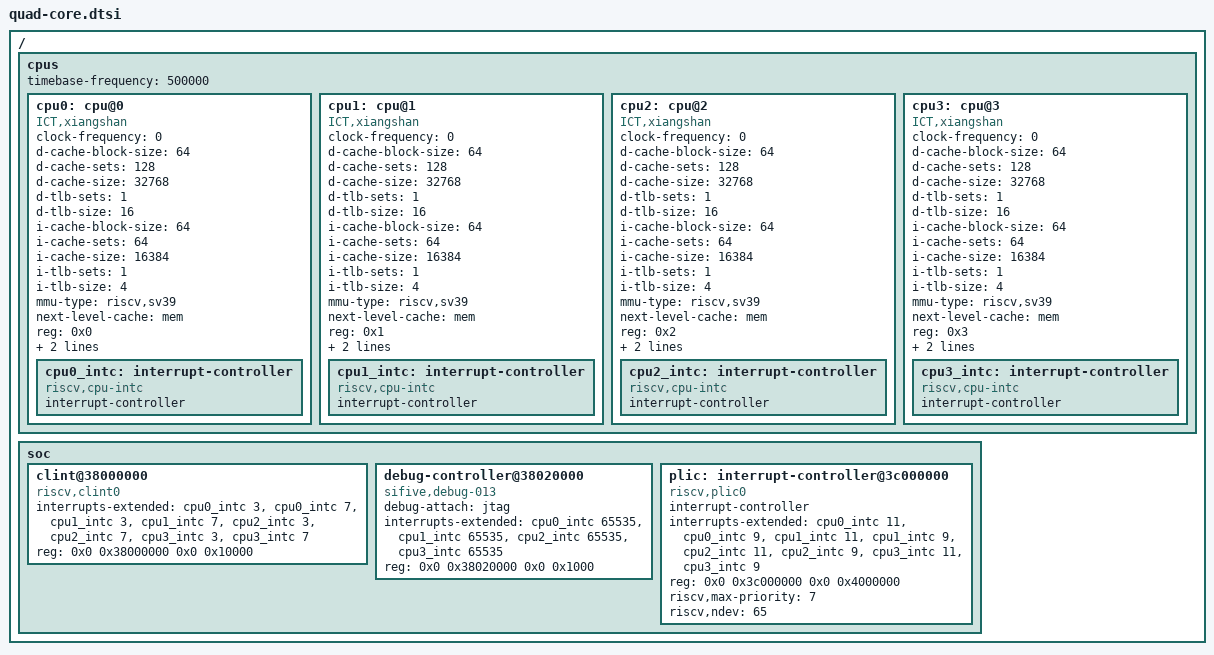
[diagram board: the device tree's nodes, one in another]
/ {
	cpus {
		#address-cells = <1>;
		#size-cells = <0>;
		timebase-frequency = <500000>;// clk freq / 100
		cpu0: cpu@0 {
			clock-frequency = <0>;
			compatible = "ICT,xiangshan", "riscv";
			d-cache-block-size = <64>;
			d-cache-sets = <128>;
			d-cache-size = <32768>;
			d-tlb-sets = <1>;
			d-tlb-size = <16>;
			device_type = "cpu";
			i-cache-block-size = <64>;
			i-cache-sets = <64>;
			i-cache-size = <16384>;
			i-tlb-sets = <1>;
			i-tlb-size = <4>;
			mmu-type = "riscv,sv39";
			next-level-cache = <&mem>;
			reg = <0x0>;
			riscv,isa = "rv64imafdc";
			status = "okay";
			tlb-split;
			cpu0_intc: interrupt-controller {
				#address-cells = <0>;
				#interrupt-cells = <1>;
				compatible = "riscv,cpu-intc";
				interrupt-controller;
			};
		};
		cpu1: cpu@1 {
			clock-frequency = <0>;
			compatible = "ICT,xiangshan", "riscv";
			d-cache-block-size = <64>;
			d-cache-sets = <128>;
			d-cache-size = <32768>;
			d-tlb-sets = <1>;
			d-tlb-size = <16>;
			device_type = "cpu";
			i-cache-block-size = <64>;
			i-cache-sets = <64>;
			i-cache-size = <16384>;
			i-tlb-sets = <1>;
			i-tlb-size = <4>;
			mmu-type = "riscv,sv39";
			next-level-cache = <&mem>;
			reg = <0x1>;
			riscv,isa = "rv64imafdc";
			status = "okay";
			tlb-split;
			cpu1_intc: interrupt-controller {
				#address-cells = <0>;
				#interrupt-cells = <1>;
				compatible = "riscv,cpu-intc";
				interrupt-controller;
			};
		};
		cpu2: cpu@2 {
			clock-frequency = <0>;
			compatible = "ICT,xiangshan", "riscv";
			d-cache-block-size = <64>;
			d-cache-sets = <128>;
			d-cache-size = <32768>;
			d-tlb-sets = <1>;
			d-tlb-size = <16>;
			device_type = "cpu";
			i-cache-block-size = <64>;
			i-cache-sets = <64>;
			i-cache-size = <16384>;
			i-tlb-sets = <1>;
			i-tlb-size = <4>;
			mmu-type = "riscv,sv39";
			next-level-cache = <&mem>;
			reg = <0x2>;
			riscv,isa = "rv64imafdc";
			status = "okay";
			tlb-split;
			cpu2_intc: interrupt-controller {
				#address-cells = <0>;
				#interrupt-cells = <1>;
				compatible = "riscv,cpu-intc";
				interrupt-controller;
			};
		};
		cpu3: cpu@3 {
			clock-frequency = <0>;
			compatible = "ICT,xiangshan", "riscv";
			d-cache-block-size = <64>;
			d-cache-sets = <128>;
			d-cache-size = <32768>;
			d-tlb-sets = <1>;
			d-tlb-size = <16>;
			device_type = "cpu";
			i-cache-block-size = <64>;
			i-cache-sets = <64>;
			i-cache-size = <16384>;
			i-tlb-sets = <1>;
			i-tlb-size = <4>;
			mmu-type = "riscv,sv39";
			next-level-cache = <&mem>;
			reg = <0x3>;
			riscv,isa = "rv64imafdc";
			status = "okay";
			tlb-split;
			cpu3_intc: interrupt-controller {
				#address-cells = <0>;
				#interrupt-cells = <1>;
				compatible = "riscv,cpu-intc";
				interrupt-controller;
			};
		};
	};
	
	soc {
		clint@38000000 {
			compatible = "riscv,clint0";
			interrupts-extended = <&cpu0_intc 3 &cpu0_intc 7 &cpu1_intc 3 &cpu1_intc 7 &cpu2_intc 3 &cpu2_intc 7 &cpu3_intc 3 &cpu3_intc 7>;
			reg = <0x0 0x38000000 0x0 0x10000>;
			reg-names = "control";
		};
		debug-controller@38020000 {
			compatible = "sifive,debug-013", "riscv,debug-013";
			debug-attach = "jtag";
			interrupts-extended = <&cpu0_intc 65535 &cpu1_intc 65535 &cpu2_intc 65535 &cpu3_intc 65535>;
			reg = <0x0 0x38020000 0x0 0x1000>;
			reg-names = "control";
		};
		plic: interrupt-controller@3c000000 {
			#address-cells = <2>;
			#interrupt-cells = <1>;
			compatible = "riscv,plic0";
			interrupt-controller;
			interrupts-extended = <&cpu0_intc 11 &cpu0_intc 9 &cpu1_intc 11 &cpu1_intc 9 &cpu2_intc 11 &cpu2_intc 9 &cpu3_intc 11 &cpu3_intc 9>;
			reg = <0x0 0x3c000000 0x0 0x4000000>;
			reg-names = "control";
			riscv,max-priority = <7>;
			riscv,ndev = <65>;
		};
	};
};
